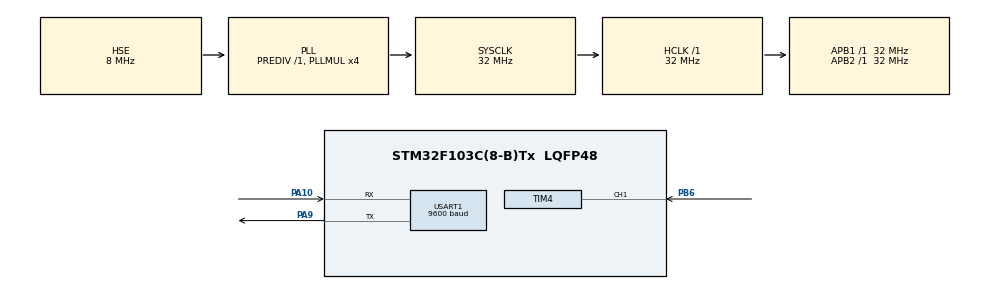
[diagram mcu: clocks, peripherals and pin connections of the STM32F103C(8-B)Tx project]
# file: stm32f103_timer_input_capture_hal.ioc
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Mcu.Family=STM32F1
Mcu.Name=STM32F103C(8-B)Tx
Mcu.Package=LQFP48
NVIC.PriorityGroup=NVIC_PRIORITYGROUP_4
NVIC.TIM4_IRQn=true\:0\:0\:false\:false\:true\:true\:true
PA10.Mode=Asynchronous
PA10.Signal=USART1_RX
PA13.Mode=Serial_Wire
PA13.Signal=SYS_JTMS-SWDIO
PA14.Mode=Serial_Wire
PA14.Signal=SYS_JTCK-SWCLK
PA9.Mode=Asynchronous
PA9.Signal=USART1_TX
PB6.Signal=S_TIM4_CH1
PD0-OSC_IN.Mode=HSE-External-Oscillator
PD0-OSC_IN.Signal=RCC_OSC_IN
PD1-OSC_OUT.Mode=HSE-External-Oscillator
PD1-OSC_OUT.Signal=RCC_OSC_OUT
ProjectManager.HeapSize=0x200
ProjectManager.StackSize=0x400
ProjectManager.TargetToolchain=STM32CubeIDE
RCC.AHBFreq_Value=32000000
RCC.APB1Freq_Value=32000000
RCC.APB1TimFreq_Value=32000000
RCC.APB2Freq_Value=32000000
RCC.APB2TimFreq_Value=32000000
RCC.HCLKFreq_Value=32000000
RCC.PLLMUL=RCC_PLL_MUL4
RCC.PLLSourceVirtual=RCC_PLLSOURCE_HSE
RCC.SYSCLKFreq_VALUE=32000000
RCC.SYSCLKSource=RCC_SYSCLKSOURCE_PLLCLK
RCC.USBFreq_Value=32000000
SH.S_TIM4_CH1.0=TIM4_CH1,Input_Capture1_from_TI1
TIM4.AutoReloadPreload=TIM_AUTORELOAD_PRELOAD_ENABLE
TIM4.Channel-Input_Capture1_from_TI1=TIM_CHANNEL_1
TIM4.ICPrescaler-Input_Capture1_from_TI1=TIM_ICPSC_DIV1
TIM4.Prescaler=32
USART1.BaudRate=9600
USART1.VirtualMode=VM_ASYNC
VP_TIM4_VS_ClockSourceINT.Mode=Internal
board=custom

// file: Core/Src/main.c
/* USER CODE BEGIN Header */
/**
  ******************************************************************************
  * @file           : main.c
  * @brief          : Main program body
  ******************************************************************************
  * @attention
  *
  * Copyright (c) 2022 STMicroelectronics.
  * All rights reserved.
  *
  * This software is licensed under terms that can be found in the LICENSE file
  * in the root directory of this software component.
  * If no LICENSE file comes with this software, it is provided AS-IS.
  *
  ******************************************************************************
  */
/* USER CODE END Header */
#include "main.h"

/* USER CODE BEGIN Includes */
#include "stdio.h"
/* USER CODE END Includes */

/* USER CODE BEGIN PM */
#define IDLE   0
#define DONE   1
#define F_CLK  32000000UL

volatile uint8_t gu8_State = IDLE;
volatile uint8_t gu8_MSG[35] = {'\0'};
volatile uint32_t gu32_T1 = 0;
volatile uint32_t gu32_T2 = 0;
volatile uint32_t gu32_Ticks = 0;
volatile uint16_t gu16_TIM4_OVC = 0;
volatile uint32_t gu32_Freq = 0;
/* USER CODE END PM */

TIM_HandleTypeDef htim4;

UART_HandleTypeDef huart1;

void SystemClock_Config(void);
static void MX_GPIO_Init(void);
static void MX_TIM4_Init(void);
static void MX_USART1_UART_Init(void);

/* USER CODE BEGIN 0 */
void HAL_TIM_IC_CaptureCallback(TIM_HandleTypeDef* htim)
{
    if(gu8_State == IDLE)
    {
        gu32_T1 = TIM4->CCR1;
        gu16_TIM4_OVC = 0;
        gu8_State = DONE;
    }
    else if(gu8_State == DONE)
    {
        gu32_T2 = TIM4->CCR1;
        gu32_Ticks = (gu32_T2 + (gu16_TIM4_OVC * 65536)) - gu32_T1;
        gu32_Freq = (uint32_t)(F_CLK/(gu32_Ticks * 32));
        if(gu32_Freq != 0)
        {
          sprintf(gu8_MSG, "Frequency = %lu Hz\n\r", gu32_Freq);
          HAL_UART_Transmit(&huart1, gu8_MSG, sizeof(gu8_MSG), 100);
        }
        gu8_State = IDLE;
    }
}

void HAL_TIM_PeriodElapsedCallback(TIM_HandleTypeDef* htim)
{
    gu16_TIM4_OVC++;
}
/* USER CODE END 0 */

int main(void)
{

  /* MCU Configuration--------------------------------------------------------*/

  /* Reset of all peripherals, Initializes the Flash interface and the Systick. */
  HAL_Init();

  /* Configure the system clock */
  SystemClock_Config();

  /* Initialize all configured peripherals */
  MX_GPIO_Init();
  MX_TIM4_Init();
  MX_USART1_UART_Init();
  /* USER CODE BEGIN 2 */
  HAL_TIM_Base_Start_IT(&htim4);
     HAL_TIM_IC_Start_IT(&htim4, TIM_CHANNEL_1);
  /* USER CODE END 2 */

  /* Infinite loop */
  while (1)
  {

  }
}

void SystemClock_Config(void)
{
  RCC_OscInitTypeDef RCC_OscInitStruct = {0};
  RCC_ClkInitTypeDef RCC_ClkInitStruct = {0};

  /** Initializes the RCC Oscillators according to the specified parameters
  * in the RCC_OscInitTypeDef structure.
  */
  RCC_OscInitStruct.OscillatorType = RCC_OSCILLATORTYPE_HSE;
  RCC_OscInitStruct.HSEState = RCC_HSE_ON;
  RCC_OscInitStruct.HSEPredivValue = RCC_HSE_PREDIV_DIV1;
  RCC_OscInitStruct.HSIState = RCC_HSI_ON;
  RCC_OscInitStruct.PLL.PLLState = RCC_PLL_ON;
  RCC_OscInitStruct.PLL.PLLSource = RCC_PLLSOURCE_HSE;
  RCC_OscInitStruct.PLL.PLLMUL = RCC_PLL_MUL4;
  if (HAL_RCC_OscConfig(&RCC_OscInitStruct) != HAL_OK)
  {
    Error_Handler();
  }
  /** Initializes the CPU, AHB and APB buses clocks
  */
  RCC_ClkInitStruct.ClockType = RCC_CLOCKTYPE_HCLK|RCC_CLOCKTYPE_SYSCLK
                              |RCC_CLOCKTYPE_PCLK1|RCC_CLOCKTYPE_PCLK2;
  RCC_ClkInitStruct.SYSCLKSource = RCC_SYSCLKSOURCE_PLLCLK;
  RCC_ClkInitStruct.AHBCLKDivider = RCC_SYSCLK_DIV1;
  RCC_ClkInitStruct.APB1CLKDivider = RCC_HCLK_DIV1;
  RCC_ClkInitStruct.APB2CLKDivider = RCC_HCLK_DIV1;

  if (HAL_RCC_ClockConfig(&RCC_ClkInitStruct, FLASH_LATENCY_1) != HAL_OK)
  {
    Error_Handler();
  }
}

static void MX_TIM4_Init(void)
{

  TIM_ClockConfigTypeDef sClockSourceConfig = {0};
  TIM_MasterConfigTypeDef sMasterConfig = {0};
  TIM_IC_InitTypeDef sConfigIC = {0};

  htim4.Instance = TIM4;
  htim4.Init.Prescaler = 32;
  htim4.Init.CounterMode = TIM_COUNTERMODE_UP;
  htim4.Init.Period = 65535;
  htim4.Init.ClockDivision = TIM_CLOCKDIVISION_DIV1;
  htim4.Init.AutoReloadPreload = TIM_AUTORELOAD_PRELOAD_ENABLE;
  if (HAL_TIM_Base_Init(&htim4) != HAL_OK)
  {
    Error_Handler();
  }
  sClockSourceConfig.ClockSource = TIM_CLOCKSOURCE_INTERNAL;
  if (HAL_TIM_ConfigClockSource(&htim4, &sClockSourceConfig) != HAL_OK)
  {
    Error_Handler();
  }
  if (HAL_TIM_IC_Init(&htim4) != HAL_OK)
  {
    Error_Handler();
  }
  sMasterConfig.MasterOutputTrigger = TIM_TRGO_RESET;
  sMasterConfig.MasterSlaveMode = TIM_MASTERSLAVEMODE_DISABLE;
  if (HAL_TIMEx_MasterConfigSynchronization(&htim4, &sMasterConfig) != HAL_OK)
  {
    Error_Handler();
  }
  sConfigIC.ICPolarity = TIM_INPUTCHANNELPOLARITY_RISING;
  sConfigIC.ICSelection = TIM_ICSELECTION_DIRECTTI;
  sConfigIC.ICPrescaler = TIM_ICPSC_DIV1;
  sConfigIC.ICFilter = 0;
  if (HAL_TIM_IC_ConfigChannel(&htim4, &sConfigIC, TIM_CHANNEL_1) != HAL_OK)
  {
    Error_Handler();
  }

}

static void MX_USART1_UART_Init(void)
{

  huart1.Instance = USART1;
  huart1.Init.BaudRate = 9600;
  huart1.Init.WordLength = UART_WORDLENGTH_8B;
  huart1.Init.StopBits = UART_STOPBITS_1;
  huart1.Init.Parity = UART_PARITY_NONE;
  huart1.Init.Mode = UART_MODE_TX_RX;
  huart1.Init.HwFlowCtl = UART_HWCONTROL_NONE;
  huart1.Init.OverSampling = UART_OVERSAMPLING_16;
  if (HAL_UART_Init(&huart1) != HAL_OK)
  {
    Error_Handler();
  }

}

static void MX_GPIO_Init(void)
{

  /* GPIO Ports Clock Enable */
  __HAL_RCC_GPIOD_CLK_ENABLE();
  __HAL_RCC_GPIOA_CLK_ENABLE();
  __HAL_RCC_GPIOB_CLK_ENABLE();

}

void Error_Handler(void)
{
  __disable_irq();
  while (1)
  {
  }
}
